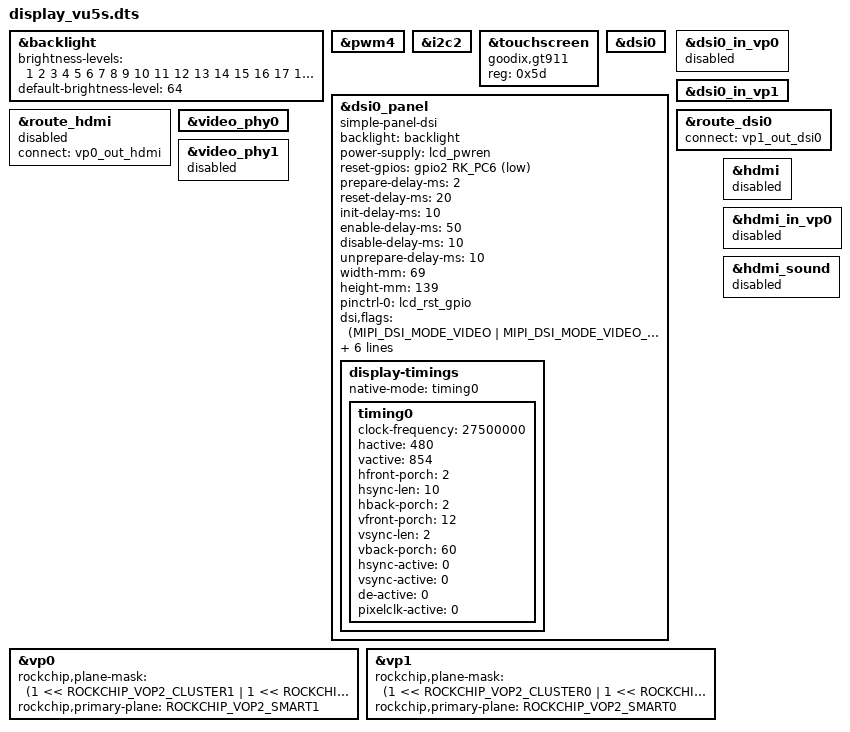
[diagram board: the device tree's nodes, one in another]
/dts-v1/;
/plugin/;

#include <dt-bindings/gpio/gpio.h>
#include <dt-bindings/pinctrl/rockchip.h>
#include <dt-bindings/display/drm_mipi_dsi.h>
#include <dt-bindings/display/rockchip_vop.h>
#include <dt-bindings/interrupt-controller/irq.h>
#include <dt-bindings/interrupt-controller/arm-gic.h>

/{
	fragment@0 {
		target = <&backlight>;

		__overlay__ {
			status = "okay";
			brightness-levels = <
				1   2   3   4   5   6   7   8
				9   10  11  12  13  14  15  16
				17  18  19  20  21  22  23  24
				25  26  27  28  29  30  31  32
				33  34  35  36  37  38  39  40
				41  42  43  44  45  46  47  48
				49  50  51  52  53  54  55  56
				57  58  59  60  61  62  63  64
				65  66  67  68  69  70  71  72
				73  74  75  76  77  78  79  80
				81  82  83  84  85  86  87  88
				89  90  91  92  93  94  95  96
				97  98  99  100 101 102 103 104
				105 106 107 108 109 110 111 112
				113 114 115 116 117 118 119 120
				121 122 123 124 125 126 127 128
				>;
			default-brightness-level = <64>;
		};
	};

	fragment@1 {
		target = <&pwm4>;

		__overlay__ {
			status = "okay";
		};
	};

	fragment@2 {
		target = <&i2c2>;

		__overlay__ {
			status = "okay";
		};
	};

	fragment@3 {
		target = <&touchscreen>;

		#address-cells = <1>;
		#size-cells = <0>;

		__overlay__ {
			status = "okay";

			compatible = "goodix,gt911";
			reg = <0x5d>;
		};
	};

	fragment@4 {
		target = <&dsi0>;

		__overlay__ {
			status = "okay";
		};
	};

	fragment@5 {
		target = <&dsi0_panel>;

		__overlay__ {
			status = "okay";
			compatible = "simple-panel-dsi";

			backlight = <&backlight>;
			power-supply = <&lcd_pwren>;
			reset-gpios = <&gpio2 RK_PC6 GPIO_ACTIVE_LOW>;

			prepare-delay-ms = <2>;
			reset-delay-ms = <20>;
			init-delay-ms = <10>;
			enable-delay-ms = <50>;
			disable-delay-ms = <10>;
			unprepare-delay-ms = <10>;

			/* LCD size */
			width-mm = <69>;
			height-mm = <139>;

			pinctrl-names = "default";
			pinctrl-0 = <&lcd_rst_gpio>;
			dsi,flags = <(MIPI_DSI_MODE_VIDEO |
				      MIPI_DSI_MODE_VIDEO_BURST |
				      MIPI_DSI_MODE_EOT_PACKET)>;
			dsi,format = <MIPI_DSI_FMT_RGB888>;
			dsi,lanes = <2>;

			panel-init-sequence = [
				05 05 01 01
				05 FA 01 11
				39 00 06 FF 77 01 00 00 10
				15 00 03 C0 E9 03
				15 00 03 C1 11 02
				15 00 03 C2 31 08
				15 00 02 CC 10
				39 00 11 B0 00 0D 14 0D 10 05 02 08
				            08 1E 05 13 11 A3 29 18
				39 00 11 B1 00 0C 14 0C 10 05 03 08
				            07 20 05 13 11 A4 29 18
				39 00 06 FF 77 01 00 00 11
				15 00 02 B0 6C
				15 00 02 B1 43
				15 00 02 B2 07
				15 00 02 B3 80
				15 00 02 B5 47
				15 00 02 B7 85
				15 00 02 B8 20
				15 00 02 B9 10
				15 00 02 C1 78
				15 00 02 C3 78
				15 FA 02 D0 88
				39 00 04 E0 00 00 02
				39 00 0C E1 08 00 0A 00 07 00 09 00 00 33 33
				39 00 0F E2 00 00 00 00 00 00 00 00 00 00 00 00 00 00
				39 00 05 E3 00 00 33 33
				15 00 03 E4 44 44
				39 00 11 E5 0E 60 A0 A0 10 60 A0 A0
				            0A 60 A0 A0 0C 60 A0 A0
				39 00 05 E6 00 00 33 33
				15 00 03 E7 44 44
				39 00 11 E8 0D 60 A0 A0 0F 60 A0 A0
				            09 60 A0 A0 0B 60 A0 A0
				39 00 08 EB 02 01 E4 E4 44 00 40
				15 00 03 EC 02 01
				39 00 11 ED AB 89 76 54 01 FF FF FF
				            FF FF FF 10 45 67 98 BA
				39 00 06 FF 77 01 00 00 00
				15 00 02 3A 70
				15 00 02 53 EC
				15 00 02 55 B3
				15 00 02 5E FF
				05 32 01 29
			];

			/* 28: DisplayOff */
			/* 10: SleepIn */
			panel-exit-sequence = [
				05 00 01 28
				05 00 01 10
			];

			display-timings {
				native-mode = <&timing0>;

				timing0: timing0 {
					clock-frequency = <27500000>;
					hactive = <480>;
					vactive = <854>;

					hfront-porch = <2>;
					hsync-len = <10>;
					hback-porch = <2>;
					vfront-porch = <12>;
					vsync-len = <2>;
					vback-porch = <60>;
					hsync-active = <0>;
					vsync-active = <0>;
					de-active = <0>;
					pixelclk-active = <0>;
				};
			};

		};
	};

	fragment@6 {
		target = <&dsi0_in_vp0>;

		__overlay__ {
			status = "disabled";
		};
	};

	fragment@7 {
		target = <&dsi0_in_vp1>;

		__overlay__ {
			status = "okay";
		};
	};

	fragment@8 {
		target = <&route_hdmi>;

		__overlay__ {
			status = "disabled";
			connect = <&vp0_out_hdmi>;
		};
	};

	fragment@9 {
		target = <&route_dsi0>;

		__overlay__ {
			status = "okay";
			connect = <&vp1_out_dsi0>;
		};
	};

	fragment@10 {
		target = <&video_phy0>;

		__overlay__ {
			status = "okay";
		};
	};

	fragment@11 {
		target = <&video_phy1>;

		__overlay__ {
			status = "disabled";
		};
	};

	fragment@12 {
		target = <&vp0>;

		__overlay__ {
			rockchip,plane-mask = <(1 << ROCKCHIP_VOP2_CLUSTER1
					| 1 << ROCKCHIP_VOP2_ESMART1
					| 1 << ROCKCHIP_VOP2_SMART1)>;
			rockchip,primary-plane = <ROCKCHIP_VOP2_SMART1>;
		};
	};

	fragment@13 {
		target = <&vp1>;

		__overlay__ {
			rockchip,plane-mask = <(1 << ROCKCHIP_VOP2_CLUSTER0
					| 1 << ROCKCHIP_VOP2_ESMART0
					| 1 << ROCKCHIP_VOP2_SMART0)>;
			rockchip,primary-plane = <ROCKCHIP_VOP2_SMART0>;
		};
	};

	fragment@14 {
		target = <&hdmi>;

		__overlay__ {
			status = "disabled";
		};
	};

	fragment@15 {
		target = <&hdmi_in_vp0>;

		__overlay__ {
			status = "disabled";
		};
	};

	fragment@16 {
		target = <&hdmi_sound>;

		__overlay__ {
			status = "disabled";
		};
	};
};
